# STM32H7R3xx register map
File version: 1.0
Registers are 32-bit, read-write, reset 0x0 unless marked. A register's access mark holds for its fields unless they carry their own. Offsets are from the block's base; [hi:lo] are bit positions; {n}, {i} and the like mark numbered series; 'fields as' and 'values as' point back to an identical list.

## FMC_Bank5_6_R — Flexible Memory Controller Bank5 & 6
Base 0x52004140
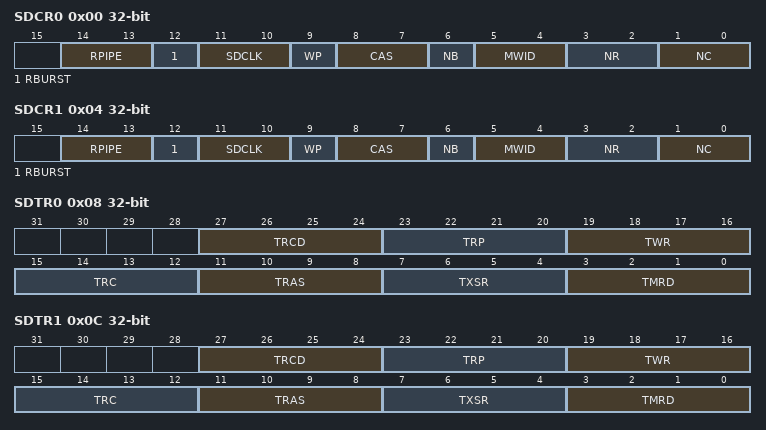
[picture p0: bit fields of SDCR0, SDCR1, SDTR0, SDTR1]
0x00 SDCR0 — SDRAM Control registers
  [14:13] RPIPE — Read pipe
  [12] RBURST — Read burst
  [11:10] SDCLK — SDRAM clock configuration
  [9] WP — Write protection
  [8:7] CAS — CAS latency
  [6] NB — Number of internal banks
  [5:4] MWID — Memory data bus width
  [3:2] NR — Number of row address bits
  [1:0] NC — Number of column address bits
0x04 SDCR1 — SDRAM Control registers
  fields as SDCR0
0x08 SDTR0 — SDRAM Timing registers
  [27:24] TRCD — Row to column delay
  [23:20] TRP — Row precharge delay
  [19:16] TWR — Recovery delay
  [15:12] TRC — Row cycle delay
  [11:8] TRAS — Self refresh time
  [7:4] TXSR — Exit self-refresh delay
  [3:0] TMRD — Load mode register to active
0x0C SDTR1 — SDRAM Timing registers
  fields as SDTR0
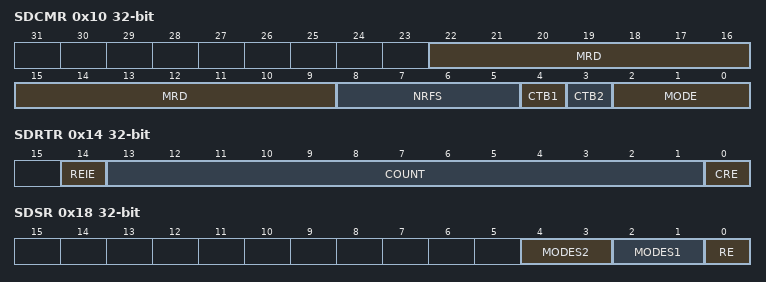
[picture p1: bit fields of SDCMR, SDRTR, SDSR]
0x10 SDCMR — SDRAM Command Mode register
  [22:9] MRD — Mode register definition
  [8:5] NRFS — Number of auto-refresh
  [4] CTB1 — Command target bank 1
  [3] CTB2 — Command target bank 2
  [2:0] MODE — Command mode
0x14 SDRTR — SDRAM Refresh Timer register
  [14] REIE — RES interrupt enable
  [13:1] COUNT — Refresh timer count
  [0] CRE — Clear refresh error flag
0x18 SDSR — SDRAM Status register
  [4:3] MODES2 — Status mode for bank 2
  [2:1] MODES1 — Status mode for bank 1
  [0] RE — Refresh error flag

## RAMECC1
Base 0x52009000
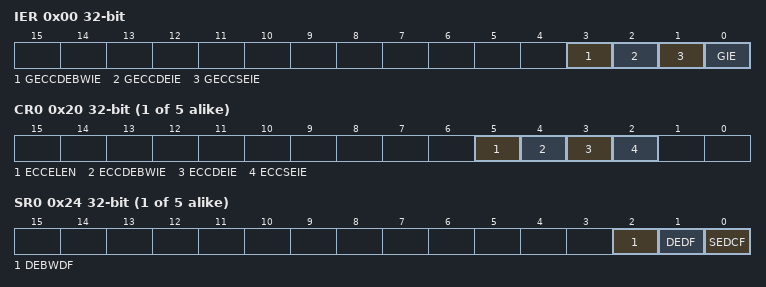
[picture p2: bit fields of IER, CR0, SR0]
0x00 IER — RAMECC interrupt enable register
  [3] GECCDEBWIE — Global ECC double error on byte write (BW) interrupt enable
  [2] GECCDEIE — Global ECC double error interrupt enable
  [1] GECCSEIE — Global ECC single error interrupt enable
  [0] GIE — Global interrupt enable
{0x20+0x20*i} CR{i} (i=0..4) — RAMECC monitor configuration register
  [5] ECCELEN — ECC error latching enable
  [4] ECCDEBWIE — ECC double error on byte write (BW) interrupt enable
  [3] ECCDEIE — ECC double error interrupt enable
  [2] ECCSEIE — ECC single error interrupt enable
{0x24+0x20*i} SR{i} (i=0..4) — RAMECC monitor status register
  [2] DEBWDF — ECC double error on byte write (BW) detected flag
  [1] DEDF — ECC double error detected flag
  [0] SEDCF — ECC single error detected and corrected flag
{0x28+0x20*i} FAR{i} (i=0..4) — RAMECC monitor failing address register
  [31:0] FADD — ECC error failing address
{0x2C+0x20*i} FDRL{i} (i=0..4) — RAMECC monitor failing data low register
  [31:0] FDATAL — Failing data low
{0x30+0x20*i} FDRH{i} (i=0..4) — RAMECC monitor failing data high register
  [31:0] FDATAH
{0x34+0x20*i} FECR{i} (i=0..4) — RAMECC monitor failing ECC error code register
  [31:0] FEC — Failing error code

## RAMECC2
Base 0x58027000
Registers as RAMECC1, without CR0, SR0, FAR0, FDRL0, FDRH0, FECR0, CR{n} (n=2..4), SR{n} (n=2..4), FAR{n} (n=2..4), FDRL{n} (n=2..4), FDRH{n} (n=2..4), FECR{n} (n=2..4).

## XSPIM — XSPI IO Manager
Base 0x5200B400
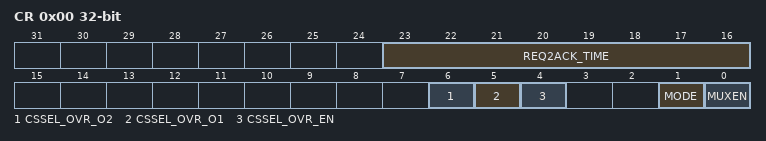
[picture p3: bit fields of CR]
0x00 CR — XSPIM IO Manager Control Register
  [23:16] REQ2ACK_TIME — REQ to ACK Time
  [6] CSSEL_OVR_O2 — Chip select selector override setting for XSPI2
  [5] CSSEL_OVR_O1 — Chip select selector override setting for XSPI1
  [4] CSSEL_OVR_EN — Chip select selector override enable
  [1] MODE — Multiplexing Mode
  [0] MUXEN — Multiplexed Mode Enable

## GFXMMU
Base 0x52010000
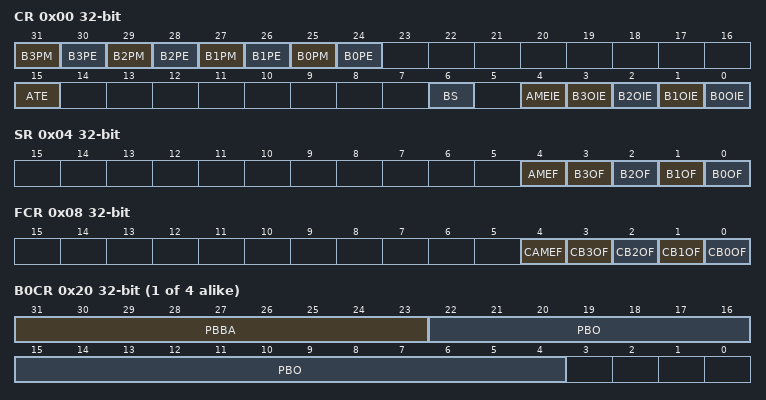
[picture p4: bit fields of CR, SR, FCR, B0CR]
0x00 CR — GFXMMU configuration register
  [31] B3PM — Buffer 0 packing mode
  [30] B3PE — Buffer 0 packing enable
  [29] B2PM — Buffer 0 packing mode
  [28] B2PE — Buffer 0 packing enable
  [27] B1PM — Buffer 1 packing mode
  [26] B1PE — Buffer 1 packing enable
  [25] B0PM — Buffer 0 packing mode
  [24] B0PE — Buffer 0 packing enable
  [15] ATE — Address translation enable
  [6] BS — Block size
  [4] AMEIE — AHB master error interrupt enable
  [n] B{n}OIE (n=0..3) — Buffer {n} overflow interrupt enable
0x04 SR — GFXMMU status register
  [4] AMEF — AXI master error flag
  [n] B{n}OF (n=0..3) — Buffer {n} overflow flag
0x08 FCR — GFXMMU flag clear register
  [4] CAMEF — Clear AHB master error flag
  [n] CB{n}OF (n=0..3) — Clear buffer {n} overflow flag
0x10 DVR — GFXMMU default value register
  [31:0] DV — DV[31:0] bits (Default value)
0x14 DAR — GFXMMU default alpha register
{0x20+4i} B{i}CR (i=0..3) — GFXMMU buffer {i} configuration register
  [31:23] PBBA — PBBA[31:23] bits (Physical buffer base address)
  [22:4] PBO — PB0[22:4] bits (Physical buffer offset)
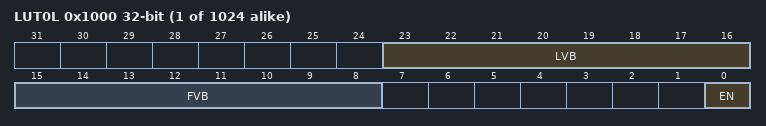
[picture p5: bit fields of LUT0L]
{0x1000+8i} LUT{i}L (i=0..1023) — GFXMMU LUT registers
  [23:16] LVB — LVB[7:0] bits (Last visible block)
  [15:8] FVB — FVB[7:0] bits (First visible block)
  [0] EN — Enable
{0x1004+8i} LUT{i}H (i=0..1023) — GFXMMU LUT registers
  [17:0] LO — LO[17:0] bits (Line offset)
